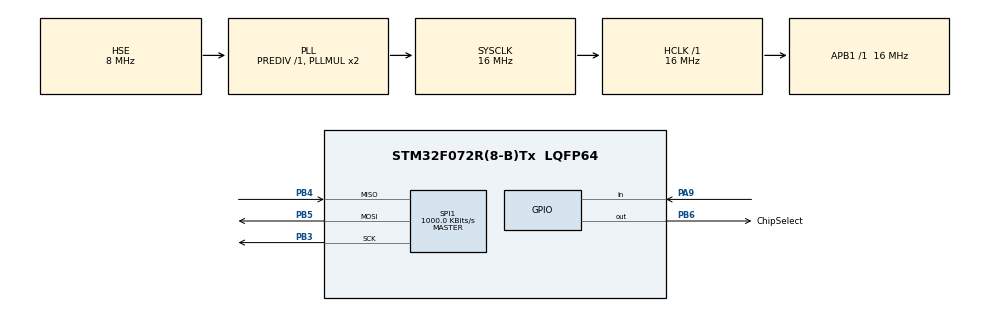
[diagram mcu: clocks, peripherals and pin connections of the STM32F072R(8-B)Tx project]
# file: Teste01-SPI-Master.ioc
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Mcu.Family=STM32F0
Mcu.Name=STM32F072R(8-B)Tx
Mcu.Package=LQFP64
NVIC.SPI1_IRQn=true\:0\:0\:false\:false\:true\:true\:true\:true
PA9.Signal=GPIO_Input
PB3.Mode=Full_Duplex_Master
PB3.Signal=SPI1_SCK
PB4.Mode=Full_Duplex_Master
PB4.Signal=SPI1_MISO
PB5.Mode=Full_Duplex_Master
PB5.Signal=SPI1_MOSI
PB6.GPIO_Label=ChipSelect
PB6.PinState=GPIO_PIN_SET
PB6.Signal=GPIO_Output
PF0-OSC_IN.Mode=HSE-External-Oscillator
PF0-OSC_IN.Signal=RCC_OSC_IN
PF1-OSC_OUT.Mode=HSE-External-Oscillator
PF1-OSC_OUT.Signal=RCC_OSC_OUT
ProjectManager.HeapSize=0x200
ProjectManager.StackSize=0x400
ProjectManager.TargetToolchain=STM32CubeIDE
RCC.AHBFreq_Value=16000000
RCC.APB1Freq_Value=16000000
RCC.APB1TimFreq_Value=16000000
RCC.HCLKFreq_Value=16000000
RCC.PLLSourceVirtual=RCC_PLLSOURCE_HSE
RCC.SYSCLKFreq_VALUE=16000000
RCC.SYSCLKSource=RCC_SYSCLKSOURCE_PLLCLK
SPI1.BaudRatePrescaler=SPI_BAUDRATEPRESCALER_16
SPI1.CalculateBaudRate=1000.0 KBits/s
SPI1.DataSize=SPI_DATASIZE_8BIT
SPI1.Direction=SPI_DIRECTION_2LINES
SPI1.Mode=SPI_MODE_MASTER
SPI1.NSSPMode=SPI_NSS_PULSE_DISABLE
SPI1.VirtualType=VM_MASTER
board=custom

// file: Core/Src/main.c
/* USER CODE BEGIN Header */
/**
  ******************************************************************************
  * @file           : main.c
  * @brief          : Main program body
  ******************************************************************************
  * @attention
  *
  * Copyright (c) 2024 STMicroelectronics.
  * All rights reserved.
  *
  * This software is licensed under terms that can be found in the LICENSE file
  * in the root directory of this software component.
  * If no LICENSE file comes with this software, it is provided AS-IS.
  *
  ******************************************************************************
  */
/* USER CODE END Header */
#include "main.h"

/* USER CODE BEGIN Includes */
//#include "<stdio.h>"

/* USER CODE END Includes */

SPI_HandleTypeDef hspi1;

/* USER CODE BEGIN PV */
uint8_t TxIdx = 0;
uint8_t RxCnt = 0;
uint8_t data_tx[10]={1,2,3,4,5,6,7,8,9,10};
uint8_t data_rx[10];
uint8_t spiRxBuffer[2];
uint8_t spiTxBuffer[2] = {0xAB,0xAB};  // Exemplo de dado a ser enviado
uint8_t spiTxBuffer2[2] = {0xAA,0xAA};

/* USER CODE END PV */

void SystemClock_Config(void);
static void MX_GPIO_Init(void);
static void MX_SPI1_Init(void);

int main(void)
{

  /* MCU Configuration--------------------------------------------------------*/

  /* Reset of all peripherals, Initializes the Flash interface and the Systick. */
  HAL_Init();

  /* USER CODE BEGIN Init */
  HAL_StatusTypeDef status;

  /* USER CODE END Init */

  /* Configure the system clock */
  SystemClock_Config();

  /* Initialize all configured peripherals */
  MX_GPIO_Init();
  MX_SPI1_Init();
  /* USER CODE BEGIN 2 */
  int c=0;

  /* USER CODE END 2 */

  /* Infinite loop */
  /* USER CODE BEGIN WHILE */
  while (1)
  {
      // 1. Abaixa o Chip Select (Pino PB6 na sua imagem)
      HAL_GPIO_WritePin(GPIOB, GPIO_PIN_6, GPIO_PIN_RESET);

      // 2. Envia os dados
      status = HAL_SPI_Transmit(&hspi1, spiTxBuffer, 2, 100);

      // 3. Levanta o Chip Select
      HAL_GPIO_WritePin(GPIOB, GPIO_PIN_6, GPIO_PIN_SET);

      if (status == HAL_OK) {
          HAL_GPIO_TogglePin(GPIOA, GPIO_PIN_9); // Pisca o LED do PA9 se enviou
      }
      HAL_Delay(1000); // Espera 1 segundo
  }
  /* USER CODE END 3 */
}

void SystemClock_Config(void)
{
  RCC_OscInitTypeDef RCC_OscInitStruct = {0};
  RCC_ClkInitTypeDef RCC_ClkInitStruct = {0};

  /** Initializes the RCC Oscillators according to the specified parameters
  * in the RCC_OscInitTypeDef structure.
  */
  RCC_OscInitStruct.OscillatorType = RCC_OSCILLATORTYPE_HSE;
  RCC_OscInitStruct.HSEState = RCC_HSE_ON;
  RCC_OscInitStruct.PLL.PLLState = RCC_PLL_ON;
  RCC_OscInitStruct.PLL.PLLSource = RCC_PLLSOURCE_HSE;
  RCC_OscInitStruct.PLL.PLLMUL = RCC_PLL_MUL2;
  RCC_OscInitStruct.PLL.PREDIV = RCC_PREDIV_DIV1;
  if (HAL_RCC_OscConfig(&RCC_OscInitStruct) != HAL_OK)
  {
    Error_Handler();
  }

  /** Initializes the CPU, AHB and APB buses clocks
  */
  RCC_ClkInitStruct.ClockType = RCC_CLOCKTYPE_HCLK|RCC_CLOCKTYPE_SYSCLK
                              |RCC_CLOCKTYPE_PCLK1;
  RCC_ClkInitStruct.SYSCLKSource = RCC_SYSCLKSOURCE_PLLCLK;
  RCC_ClkInitStruct.AHBCLKDivider = RCC_SYSCLK_DIV1;
  RCC_ClkInitStruct.APB1CLKDivider = RCC_HCLK_DIV1;

  if (HAL_RCC_ClockConfig(&RCC_ClkInitStruct, FLASH_LATENCY_0) != HAL_OK)
  {
    Error_Handler();
  }
}

static void MX_SPI1_Init(void)
{

  /* SPI1 parameter configuration*/
  hspi1.Instance = SPI1;
  hspi1.Init.Mode = SPI_MODE_MASTER;
  hspi1.Init.Direction = SPI_DIRECTION_2LINES;
  hspi1.Init.DataSize = SPI_DATASIZE_8BIT;
  hspi1.Init.CLKPolarity = SPI_POLARITY_LOW;
  hspi1.Init.CLKPhase = SPI_PHASE_1EDGE;
  hspi1.Init.NSS = SPI_NSS_SOFT;
  hspi1.Init.BaudRatePrescaler = SPI_BAUDRATEPRESCALER_16;
  hspi1.Init.FirstBit = SPI_FIRSTBIT_MSB;
  hspi1.Init.TIMode = SPI_TIMODE_DISABLE;
  hspi1.Init.CRCCalculation = SPI_CRCCALCULATION_DISABLE;
  hspi1.Init.CRCPolynomial = 7;
  hspi1.Init.CRCLength = SPI_CRC_LENGTH_DATASIZE;
  hspi1.Init.NSSPMode = SPI_NSS_PULSE_DISABLE;
  if (HAL_SPI_Init(&hspi1) != HAL_OK)
  {
    Error_Handler();
  }

}

static void MX_GPIO_Init(void)
{
  GPIO_InitTypeDef GPIO_InitStruct = {0};

  /* GPIO Ports Clock Enable */
  __HAL_RCC_GPIOF_CLK_ENABLE();
  __HAL_RCC_GPIOA_CLK_ENABLE();
  __HAL_RCC_GPIOB_CLK_ENABLE();

  /*Configure GPIO pin Output Level */
  HAL_GPIO_WritePin(ChipSelect_GPIO_Port, ChipSelect_Pin, GPIO_PIN_SET);

  /*Configure GPIO pin : PA9 */
  GPIO_InitStruct.Pin = GPIO_PIN_9;
  GPIO_InitStruct.Mode = GPIO_MODE_INPUT;
  GPIO_InitStruct.Pull = GPIO_NOPULL;
  HAL_GPIO_Init(GPIOA, &GPIO_InitStruct);

  /*Configure GPIO pin : ChipSelect_Pin */
  GPIO_InitStruct.Pin = ChipSelect_Pin;
  GPIO_InitStruct.Mode = GPIO_MODE_OUTPUT_PP;
  GPIO_InitStruct.Pull = GPIO_NOPULL;
  GPIO_InitStruct.Speed = GPIO_SPEED_FREQ_LOW;
  HAL_GPIO_Init(ChipSelect_GPIO_Port, &GPIO_InitStruct);

}

void Error_Handler(void)
{
  __disable_irq();
  while (1)
  {
  }
}
